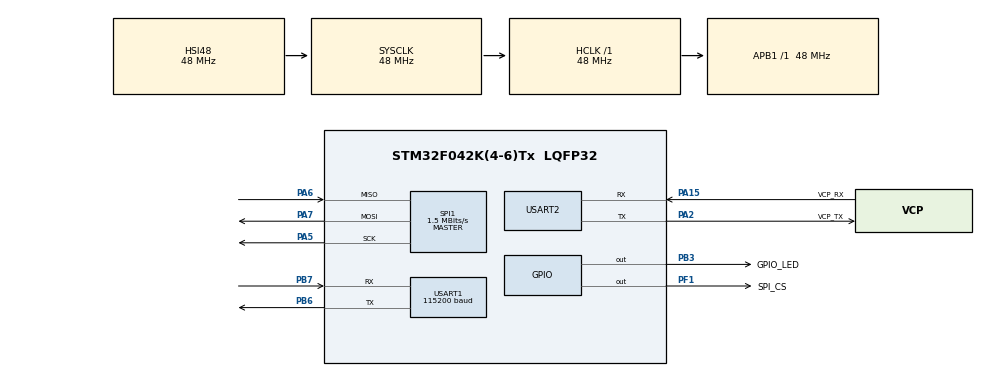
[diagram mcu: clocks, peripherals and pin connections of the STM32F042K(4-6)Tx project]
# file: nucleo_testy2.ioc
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Mcu.Family=STM32F0
Mcu.Name=STM32F042K(4-6)Tx
Mcu.Package=LQFP32
PA13.GPIO_Label=SWDIO
PA13.Mode=Serial_Wire
PA13.Signal=SYS_SWDIO
PA14.GPIO_Label=SWCLK
PA14.Mode=Serial_Wire
PA14.Signal=SYS_SWCLK
PA15.GPIO_Label=VCP_RX
PA15.Mode=Asynchronous
PA15.Signal=USART2_RX
PA2.GPIO_Label=VCP_TX
PA2.Mode=Asynchronous
PA2.Signal=USART2_TX
PA5.Mode=Full_Duplex_Master
PA5.Signal=SPI1_SCK
PA6.Mode=Full_Duplex_Master
PA6.Signal=SPI1_MISO
PA7.Mode=Full_Duplex_Master
PA7.Signal=SPI1_MOSI
PB3.GPIO_Label=GPIO_LED
PB3.Signal=GPIO_Output
PB6.Mode=Asynchronous
PB6.Signal=USART1_TX
PB7.Mode=Asynchronous
PB7.Signal=USART1_RX
PF0-OSC_IN.GPIO_Label=MCO
PF0-OSC_IN.Mode=HSE-External-Clock-Source
PF0-OSC_IN.Signal=RCC_OSC_IN
PF1-OSC_OUT.GPIO_Label=SPI_CS
PF1-OSC_OUT.GPIO_Speed=GPIO_SPEED_FREQ_HIGH
PF1-OSC_OUT.PinState=GPIO_PIN_SET
PF1-OSC_OUT.Signal=GPIO_Output
ProjectManager.HeapSize=0x200
ProjectManager.StackSize=0x400
ProjectManager.TargetToolchain=STM32CubeIDE
RCC.AHBFreq_Value=48000000
RCC.APB1Freq_Value=48000000
RCC.APB1TimFreq_Value=48000000
RCC.HCLKFreq_Value=48000000
RCC.SYSCLKFreq_VALUE=48000000
RCC.SYSCLKSource=RCC_SYSCLKSOURCE_HSI48
SPI1.BaudRatePrescaler=SPI_BAUDRATEPRESCALER_32
SPI1.CLKPolarity=SPI_POLARITY_HIGH
SPI1.CalculateBaudRate=1.5 MBits/s
SPI1.DataSize=SPI_DATASIZE_8BIT
SPI1.Direction=SPI_DIRECTION_2LINES
SPI1.Mode=SPI_MODE_MASTER
SPI1.VirtualType=VM_MASTER
USART1.BaudRate=115200
USART1.VirtualMode-Asynchronous=VM_ASYNC
USART2.VirtualMode-Asynchronous=VM_ASYNC
board=NUCLEO-F042K6

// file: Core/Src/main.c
/* USER CODE BEGIN Header */
/**
  ******************************************************************************
  * @file           : main.c
  * @brief          : Main program body
  ******************************************************************************
  * @attention
  *
  * Copyright (c) 2025 STMicroelectronics.
  * All rights reserved.
  *
  * This software is licensed under terms that can be found in the LICENSE file
  * in the root directory of this software component.
  * If no LICENSE file comes with this software, it is provided AS-IS.
  *
  ******************************************************************************
  */
/* USER CODE END Header */
#include "main.h"
#include "spi.h"
#include "usart.h"
#include "gpio.h"

/* USER CODE BEGIN Includes */
#include "asm330lhh_demo.h"
/* USER CODE END Includes */

void SystemClock_Config(void);

int main(void)
{

  /* MCU Configuration--------------------------------------------------------*/

  /* Reset of all peripherals, Initializes the Flash interface and the Systick. */
  HAL_Init();

  /* Configure the system clock */
  SystemClock_Config();

  /* Initialize all configured peripherals */
  MX_GPIO_Init();
  MX_USART2_UART_Init();
  MX_SPI1_Init();
  MX_USART1_UART_Init();
  /* USER CODE BEGIN 2 */

  start_demo();
  /* USER CODE END 2 */

  /* Infinite loop */
  while (1)
  {

  }
}

void SystemClock_Config(void)
{
  RCC_OscInitTypeDef RCC_OscInitStruct = {0};
  RCC_ClkInitTypeDef RCC_ClkInitStruct = {0};
  RCC_PeriphCLKInitTypeDef PeriphClkInit = {0};

  /** Initializes the RCC Oscillators according to the specified parameters
  * in the RCC_OscInitTypeDef structure.
  */
  RCC_OscInitStruct.OscillatorType = RCC_OSCILLATORTYPE_HSI48;
  RCC_OscInitStruct.HSI48State = RCC_HSI48_ON;
  RCC_OscInitStruct.PLL.PLLState = RCC_PLL_NONE;
  if (HAL_RCC_OscConfig(&RCC_OscInitStruct) != HAL_OK)
  {
    Error_Handler();
  }

  /** Initializes the CPU, AHB and APB buses clocks
  */
  RCC_ClkInitStruct.ClockType = RCC_CLOCKTYPE_HCLK|RCC_CLOCKTYPE_SYSCLK
                              |RCC_CLOCKTYPE_PCLK1;
  RCC_ClkInitStruct.SYSCLKSource = RCC_SYSCLKSOURCE_HSI48;
  RCC_ClkInitStruct.AHBCLKDivider = RCC_SYSCLK_DIV1;
  RCC_ClkInitStruct.APB1CLKDivider = RCC_HCLK_DIV1;

  if (HAL_RCC_ClockConfig(&RCC_ClkInitStruct, FLASH_LATENCY_1) != HAL_OK)
  {
    Error_Handler();
  }
  PeriphClkInit.PeriphClockSelection = RCC_PERIPHCLK_USART1;
  PeriphClkInit.Usart1ClockSelection = RCC_USART1CLKSOURCE_PCLK1;
  if (HAL_RCCEx_PeriphCLKConfig(&PeriphClkInit) != HAL_OK)
  {
    Error_Handler();
  }
}

void Error_Handler(void)
{
  __disable_irq();
  while (1)
  {
  }
}
